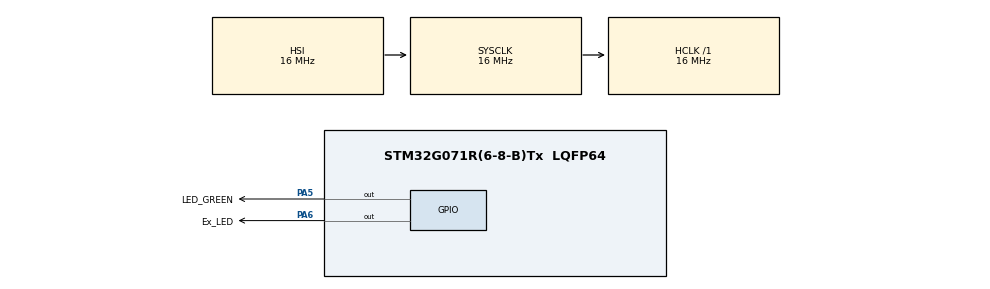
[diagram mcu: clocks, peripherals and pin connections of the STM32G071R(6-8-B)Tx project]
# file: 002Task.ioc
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FREERTOS.Tasks01=defaultTask,24,128,StartDefaultTask,Default,NULL,Dynamic,NULL,NULL;myTask01,8,128,StartTask02,Default,NULL,Dynamic,NULL,NULL
Mcu.Family=STM32G0
Mcu.Name=STM32G071R(6-8-B)Tx
Mcu.Package=LQFP64
PA13.GPIO_Label=TMS
PA13.Signal=SYS_SWDIO
PA14-BOOT0.GPIO_Label=TCK
PA14-BOOT0.Signal=SYS_SWCLK
PA2.GPIO_Label=USART2_TX [STLK_TX]
PA2.Signal=USART2_TX
PA3.GPIO_Label=USART2_RX [STLK_RX]
PA3.Signal=USART2_RX
PA5.GPIO_Label=LED_GREEN
PA5.GPIO_Speed=GPIO_SPEED_FREQ_HIGH
PA5.Signal=GPIO_Output
PA6.GPIO_Label=Ex_LED
PA6.Signal=GPIO_Output
PC13.Signal=SYS_WKUP2
PC14-OSC32_IN\ (PC14).Signal=RCC_OSC32_IN
PC15-OSC32_OUT\ (PC15).Signal=RCC_OSC32_OUT
PF0-OSC_IN\ (PF0).GPIO_Label=MCO
PF0-OSC_IN\ (PF0).Signal=RCC_OSC_IN
ProjectManager.HeapSize=0x200
ProjectManager.StackSize=0x400
ProjectManager.TargetToolchain=STM32CubeIDE
RCC.AHBFreq_Value=16000000
RCC.CortexFreq_Value=16000000
RCC.EXTERNAL_CLOCK_VALUE=12288000
RCC.HCLKFreq_Value=16000000
RCC.HSE_VALUE=8000000
RCC.HSI_VALUE=16000000
RCC.LSE_VALUE=32768
RCC.SYSCLKFreq_VALUE=16000000
RCC.VCOOutputFreq_Value=128000000
VP_FREERTOS_VS_CMSIS_V2.Mode=CMSIS_V2
VP_SYS_VS_DBSignals.Mode=DisableDeadBatterySignals
board=NUCLEO-G071RB

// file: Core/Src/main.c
/* USER CODE BEGIN Header */
/**
  ******************************************************************************
  * @file           : main.c
  * @brief          : Main program body
  ******************************************************************************
  * @attention
  *
  * <h2><center>&copy; Copyright (c) 2023 STMicroelectronics.
  * All rights reserved.</center></h2>
  *
  * This software component is licensed by ST under BSD 3-Clause license,
  * the "License"; You may not use this file except in compliance with the
  * License. You may obtain a copy of the License at:
  *                        opensource.org/licenses/BSD-3-Clause
  *
  ******************************************************************************
  */
/* USER CODE END Header */
#include "main.h"
#include "cmsis_os.h"

/* Definitions for defaultTask */
osThreadId_t defaultTaskHandle;
const osThreadAttr_t defaultTask_attributes = {
  .name = "defaultTask",
  .priority = (osPriority_t) osPriorityNormal,
  .stack_size = 128 * 4
};
/* Definitions for myTask01 */
osThreadId_t myTask01Handle;
const osThreadAttr_t myTask01_attributes = {
  .name = "myTask01",
  .priority = (osPriority_t) osPriorityLow,
  .stack_size = 128 * 4
};

void SystemClock_Config(void);
static void MX_GPIO_Init(void);
void StartDefaultTask(void *argument);
void StartTask02(void *argument);

int main(void)
{

  /* MCU Configuration--------------------------------------------------------*/

  /* Reset of all peripherals, Initializes the Flash interface and the Systick. */
  HAL_Init();

  /* Configure the system clock */
  SystemClock_Config();

  /* Initialize all configured peripherals */
  MX_GPIO_Init();

  /* Init scheduler */
  osKernelInitialize();

  /* Create the thread(s) */
  /* creation of defaultTask */
  defaultTaskHandle = osThreadNew(StartDefaultTask, NULL, &defaultTask_attributes);

  /* creation of myTask01 */
  myTask01Handle = osThreadNew(StartTask02, NULL, &myTask01_attributes);

  /* Start scheduler */
  osKernelStart();

  /* We should never get here as control is now taken by the scheduler */
  /* Infinite loop */
  while (1)
  {

  }
}

void SystemClock_Config(void)
{
  RCC_OscInitTypeDef RCC_OscInitStruct = {0};
  RCC_ClkInitTypeDef RCC_ClkInitStruct = {0};

  /** Configure the main internal regulator output voltage
  */
  HAL_PWREx_ControlVoltageScaling(PWR_REGULATOR_VOLTAGE_SCALE1);
  /** Initializes the RCC Oscillators according to the specified parameters
  * in the RCC_OscInitTypeDef structure.
  */
  RCC_OscInitStruct.OscillatorType = RCC_OSCILLATORTYPE_HSI;
  RCC_OscInitStruct.HSIState = RCC_HSI_ON;
  RCC_OscInitStruct.HSIDiv = RCC_HSI_DIV1;
  RCC_OscInitStruct.HSICalibrationValue = RCC_HSICALIBRATION_DEFAULT;
  RCC_OscInitStruct.PLL.PLLState = RCC_PLL_NONE;
  if (HAL_RCC_OscConfig(&RCC_OscInitStruct) != HAL_OK)
  {
    Error_Handler();
  }
  /** Initializes the CPU, AHB and APB buses clocks
  */
  RCC_ClkInitStruct.ClockType = RCC_CLOCKTYPE_HCLK|RCC_CLOCKTYPE_SYSCLK
                              |RCC_CLOCKTYPE_PCLK1;
  RCC_ClkInitStruct.SYSCLKSource = RCC_SYSCLKSOURCE_HSI;
  RCC_ClkInitStruct.AHBCLKDivider = RCC_SYSCLK_DIV1;
  RCC_ClkInitStruct.APB1CLKDivider = RCC_HCLK_DIV1;

  if (HAL_RCC_ClockConfig(&RCC_ClkInitStruct, FLASH_LATENCY_0) != HAL_OK)
  {
    Error_Handler();
  }
}

static void MX_GPIO_Init(void)
{
  GPIO_InitTypeDef GPIO_InitStruct = {0};

  /* GPIO Ports Clock Enable */
  __HAL_RCC_GPIOC_CLK_ENABLE();
  __HAL_RCC_GPIOF_CLK_ENABLE();
  __HAL_RCC_GPIOA_CLK_ENABLE();

  /*Configure GPIO pin Output Level */
  HAL_GPIO_WritePin(GPIOA, LED_GREEN_Pin|Ex_LED_Pin, GPIO_PIN_RESET);

  /*Configure GPIO pins : USART2_TX_Pin USART2_RX_Pin */
  GPIO_InitStruct.Pin = USART2_TX_Pin|USART2_RX_Pin;
  GPIO_InitStruct.Mode = GPIO_MODE_AF_PP;
  GPIO_InitStruct.Pull = GPIO_NOPULL;
  GPIO_InitStruct.Speed = GPIO_SPEED_FREQ_LOW;
  GPIO_InitStruct.Alternate = GPIO_AF1_USART2;
  HAL_GPIO_Init(GPIOA, &GPIO_InitStruct);

  /*Configure GPIO pin : LED_GREEN_Pin */
  GPIO_InitStruct.Pin = LED_GREEN_Pin;
  GPIO_InitStruct.Mode = GPIO_MODE_OUTPUT_PP;
  GPIO_InitStruct.Pull = GPIO_NOPULL;
  GPIO_InitStruct.Speed = GPIO_SPEED_FREQ_HIGH;
  HAL_GPIO_Init(LED_GREEN_GPIO_Port, &GPIO_InitStruct);

  /*Configure GPIO pin : Ex_LED_Pin */
  GPIO_InitStruct.Pin = Ex_LED_Pin;
  GPIO_InitStruct.Mode = GPIO_MODE_OUTPUT_PP;
  GPIO_InitStruct.Pull = GPIO_NOPULL;
  GPIO_InitStruct.Speed = GPIO_SPEED_FREQ_LOW;
  HAL_GPIO_Init(Ex_LED_GPIO_Port, &GPIO_InitStruct);

}

void StartDefaultTask(void *argument)
{
  /* USER CODE BEGIN 5 */
  /* Infinite loop */
  for(;;)
  {
    HAL_GPIO_TogglePin(LED_GREEN_GPIO_Port, LED_GREEN_Pin);
    osDelay(1000);
  }
  /* USER CODE END 5 */
}

void StartTask02(void *argument)
{
  /* USER CODE BEGIN StartTask02 */
  /* Infinite loop */
  for(;;)
  {
	  HAL_GPIO_TogglePin(Ex_LED_GPIO_Port,Ex_LED_Pin);
	  osDelay(1000);
  }
  /* USER CODE END StartTask02 */
}

void Error_Handler(void)
{
  __disable_irq();
  while (1)
  {
  }
}

/************************ (C) COPYRIGHT STMicroelectronics *****END OF FILE****/
